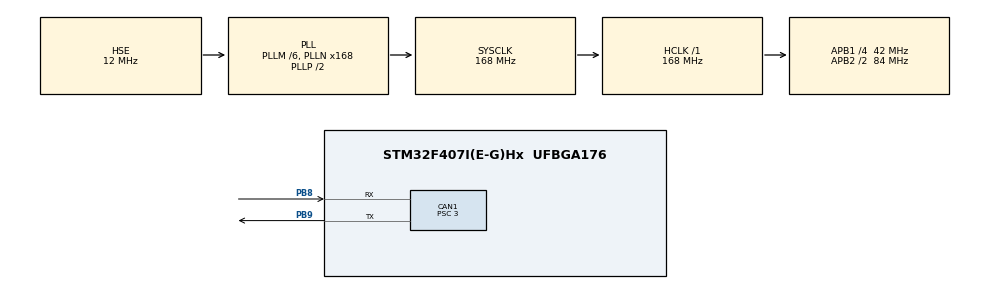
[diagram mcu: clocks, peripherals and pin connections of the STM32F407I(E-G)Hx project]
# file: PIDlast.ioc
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CAN1.BS1=CAN_BS1_10TQ
CAN1.BS2=CAN_BS2_3TQ
CAN1.CalculateBaudRate=1000000
CAN1.CalculateTimeBit=1000
CAN1.CalculateTimeQuantum=71.42857142857143
CAN1.Prescaler=3
Mcu.Family=STM32F4
Mcu.Name=STM32F407I(E-G)Hx
Mcu.Package=UFBGA176
NVIC.CAN1_RX0_IRQn=true\:0\:0\:false\:false\:true\:true\:true\:true
NVIC.PriorityGroup=NVIC_PRIORITYGROUP_4
PA13.Mode=Serial_Wire
PA13.Signal=SYS_JTMS-SWDIO
PA14.Mode=Serial_Wire
PA14.Signal=SYS_JTCK-SWCLK
PB8.Mode=CAN_Activate
PB8.Signal=CAN1_RX
PB9.Mode=CAN_Activate
PB9.Signal=CAN1_TX
PH0-OSC_IN.Mode=HSE-External-Oscillator
PH0-OSC_IN.Signal=RCC_OSC_IN
PH1-OSC_OUT.Mode=HSE-External-Oscillator
PH1-OSC_OUT.Signal=RCC_OSC_OUT
ProjectManager.HeapSize=0x200
ProjectManager.StackSize=0x400
ProjectManager.TargetToolchain=MDK-ARM V5.32
RCC.48MHZClocksFreq_Value=84000000
RCC.AHBFreq_Value=168000000
RCC.APB1CLKDivider=RCC_HCLK_DIV4
RCC.APB1Freq_Value=42000000
RCC.APB1TimFreq_Value=84000000
RCC.APB2CLKDivider=RCC_HCLK_DIV2
RCC.APB2Freq_Value=84000000
RCC.APB2TimFreq_Value=168000000
RCC.CortexFreq_Value=168000000
RCC.HCLKFreq_Value=168000000
RCC.HSE_VALUE=12000000
RCC.HSI_VALUE=16000000
RCC.LSE_VALUE=32768
RCC.PLLM=6
RCC.PLLN=168
RCC.PLLSourceVirtual=RCC_PLLSOURCE_HSE
RCC.SYSCLKFreq_VALUE=168000000
RCC.SYSCLKSource=RCC_SYSCLKSOURCE_PLLCLK
RCC.VCOOutputFreq_Value=336000000
board=custom

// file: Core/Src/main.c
/* USER CODE BEGIN Header */
/**
  ******************************************************************************
  * @file           : main.c
  * @brief          : Main program body
  ******************************************************************************
  * @attention
  *
  * Copyright (c) 2025 STMicroelectronics.
  * All rights reserved.
  *
  * This software is licensed under terms that can be found in the LICENSE file
  * in the root directory of this software component.
  * If no LICENSE file comes with this software, it is provided AS-IS.
  *
  ******************************************************************************
  */
/* USER CODE END Header */
#include "main.h"
#include "can.h"
#include "gpio.h"

/* USER CODE BEGIN Includes */
#include "bsp_can.h"
#include "CAN_receive.h"
#include "pid.h"
/* USER CODE END Includes */

void SystemClock_Config(void);
/* USER CODE BEGIN PFP */
pid_type_def              motor_pid;      //声明PID数据结构体1
extern PID_TypeDef   drive_motor_pid[4];  //声明PID数据结构体2

const motor_measure_t    *motor_data[4];  //声明电机结构体指针

int    set_speed = 0 ;                    //目标速度
const  fp32  PID[3] = { 10 ,0.02, 0.1};     //P,I,D

/* USER CODE END PFP */

int main(void)
{

  /* MCU Configuration--------------------------------------------------------*/

  /* Reset of all peripherals, Initializes the Flash interface and the Systick. */
  HAL_Init();

  /* Configure the system clock */
  SystemClock_Config();

  /* Initialize all configured peripherals */
  MX_GPIO_Init();
  MX_CAN1_Init();
  /* USER CODE BEGIN 2 */
  can_filter_init();//滤波器初始化
     //各电机pid参数的初始化
	 for(int di=0; di<4; di++)
  {
      pid_init(&drive_motor_pid[di]);
      drive_motor_pid[di].f_param_init(&drive_motor_pid[di], PID_Speed, 16384, 5000, 10, 0, 8000, 0,  10, 0.02, 0.1);
  }
	//获取各电机的状态值
	motor_data[0] = get_chassis_motor_measure_point(0);//获取ID为1号的电机数据指针
	motor_data[1] = get_chassis_motor_measure_point(1);//获取ID为2号的电机数据指针
	motor_data[2] = get_chassis_motor_measure_point(2);//获取ID为3号的电机数据指针
	motor_data[3] = get_chassis_motor_measure_point(3);//获取ID为4号的电机数据指针

  /* USER CODE END 2 */

  /* Infinite loop */
  while (1)
  {

    /* USER CODE BEGIN 3 */

      chassis_motor(600);
  }
  /* USER CODE END 3 */
}

void SystemClock_Config(void)
{
  RCC_OscInitTypeDef RCC_OscInitStruct = {0};
  RCC_ClkInitTypeDef RCC_ClkInitStruct = {0};

  /** Configure the main internal regulator output voltage
  */
  __HAL_RCC_PWR_CLK_ENABLE();
  __HAL_PWR_VOLTAGESCALING_CONFIG(PWR_REGULATOR_VOLTAGE_SCALE1);

  /** Initializes the RCC Oscillators according to the specified parameters
  * in the RCC_OscInitTypeDef structure.
  */
  RCC_OscInitStruct.OscillatorType = RCC_OSCILLATORTYPE_HSE;
  RCC_OscInitStruct.HSEState = RCC_HSE_ON;
  RCC_OscInitStruct.PLL.PLLState = RCC_PLL_ON;
  RCC_OscInitStruct.PLL.PLLSource = RCC_PLLSOURCE_HSE;
  RCC_OscInitStruct.PLL.PLLM = 6;
  RCC_OscInitStruct.PLL.PLLN = 168;
  RCC_OscInitStruct.PLL.PLLP = RCC_PLLP_DIV2;
  RCC_OscInitStruct.PLL.PLLQ = 4;
  if (HAL_RCC_OscConfig(&RCC_OscInitStruct) != HAL_OK)
  {
    Error_Handler();
  }

  /** Initializes the CPU, AHB and APB buses clocks
  */
  RCC_ClkInitStruct.ClockType = RCC_CLOCKTYPE_HCLK|RCC_CLOCKTYPE_SYSCLK
                              |RCC_CLOCKTYPE_PCLK1|RCC_CLOCKTYPE_PCLK2;
  RCC_ClkInitStruct.SYSCLKSource = RCC_SYSCLKSOURCE_PLLCLK;
  RCC_ClkInitStruct.AHBCLKDivider = RCC_SYSCLK_DIV1;
  RCC_ClkInitStruct.APB1CLKDivider = RCC_HCLK_DIV4;
  RCC_ClkInitStruct.APB2CLKDivider = RCC_HCLK_DIV2;

  if (HAL_RCC_ClockConfig(&RCC_ClkInitStruct, FLASH_LATENCY_5) != HAL_OK)
  {
    Error_Handler();
  }
}

/* USER CODE BEGIN 4 */
void chassis_motor ( float v )
{
		//设置转速值
		drive_motor_pid[0].target = 600;
		drive_motor_pid[1].target = 600;
		drive_motor_pid[2].target = 600;
		drive_motor_pid[3].target = 600;

		drive_motor_pid[0].f_cal_pid(&drive_motor_pid[0],motor_data[0]->speed_rpm);   //1号电机的pid电流计算值
		drive_motor_pid[1].f_cal_pid(&drive_motor_pid[1],motor_data[1]->speed_rpm);   //2号电机的pid电流计算值
		drive_motor_pid[2].f_cal_pid(&drive_motor_pid[2],motor_data[2]->speed_rpm);   //3号电机的pid电流计算值
		drive_motor_pid[3].f_cal_pid(&drive_motor_pid[3],motor_data[3]->speed_rpm);   //4号电机的pid电流计算值

		CAN_cmd_chassis(drive_motor_pid[0].output,drive_motor_pid[1].output,drive_motor_pid[2].output,drive_motor_pid[3].output);
		HAL_Delay(2);
}

/* USER CODE END 4 */

void Error_Handler(void)
{
  __disable_irq();
  while (1)
  {
  }
}
